# CY8C5868AXI_LP035 register map
File version: 0.1
CY8C58LP
Registers are 8-bit, read-write, no defined reset value unless marked. A register's access mark holds for its fields unless they carry their own. Offsets are from the block's base; lines under a group give offsets from that group; [hi:lo] are bit positions; {n}, {i} and the like mark numbered series; 'fields as' and 'values as' point back to an identical list; <NAME> marks a mode.

## Memory map
0x00000000 PWM_Regulering
0x00000000 PWM_Speed
0x00000000 Counter_Speed
0x00000000 AD_konverter_SAR — SAR ADC
0x00000000 UART

## PWM_Regulering
Base 0x00000000
0x40006428 PWM_Regulering_COMPARE_Reg_ — UDB.D0 - Assigned Compare Value
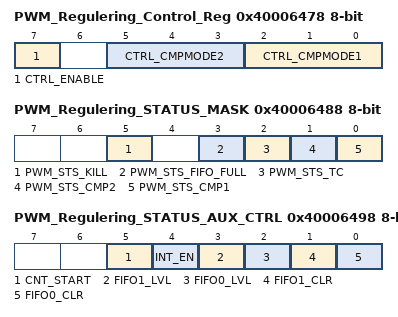
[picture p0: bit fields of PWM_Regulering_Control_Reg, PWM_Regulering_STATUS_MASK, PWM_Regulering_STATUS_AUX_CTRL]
0x40006478 PWM_Regulering_Control_Reg — UDB Control Register - Assigned Control Register Value
  [7] CTRL_ENABLE — Enable the PWM
  [5:3] CTRL_CMPMODE2 — Compare mode 2
  [2:0] CTRL_CMPMODE1 — Compare mode 1
0x40006488 PWM_Regulering_STATUS_MASK — UDB Status bits Interrupt Mask Enable Register
  [5] PWM_STS_KILL ro — Enables the Interrupt on Kill
  [3] PWM_STS_FIFO_FULL ro — FIFO Full Status Mask
  [2] PWM_STS_TC ro — Enables the Interrupt on Terminal Count
  [1] PWM_STS_CMP2 ro — Enables the Interrupt on Compare 2
  [0] PWM_STS_CMP1 ro — Enables the Interrupt on Compare 1
0x40006498 PWM_Regulering_STATUS_AUX_CTRL — UDB Auxilliary Control Register
  [5] CNT_START — FIFO0 clear
    0=E_CNT_START0 (Disable counter); 1=E_CNT_START1 (Enable counter)
  [4] INT_EN
    0=E_INT_EN0 (Interrupt disabled); 1=E_INT_EN1 (Interrupt enabled)
  [3] FIFO1_LVL — FIFO level
    0=E_FIFO_LVL_0 (FIFO LVL: input mode: FIFO not full; output mode: FIFO not empty); 1=E_FIFO_LVL_1 (FIFO LVL: input mode: FIFO at least 1/2 empty; output mode: FIFO at least 1/2 full)
  [2] FIFO0_LVL — FIFO level
    values as FIFO1_LVL
  [1] FIFO1_CLR — FIFO1 clear
    0=E_FIFO_CLR_0 (Normal FIFO operation); 1=E_FIFO_CLR_1 (Clear FIFO state)
  [0] FIFO0_CLR — FIFO0 clear
    values as FIFO1_CLR

## PWM_Speed
Base 0x00000000
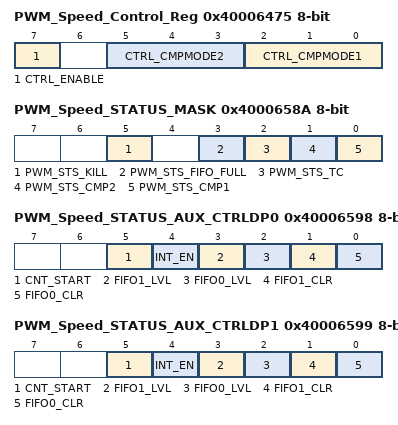
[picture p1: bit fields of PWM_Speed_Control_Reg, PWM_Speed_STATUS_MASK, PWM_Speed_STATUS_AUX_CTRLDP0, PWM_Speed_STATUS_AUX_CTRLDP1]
0x40006475 PWM_Speed_Control_Reg — UDB Control Register - Assigned Control Register Value
  [7] CTRL_ENABLE — Enable the PWM
  [5:3] CTRL_CMPMODE2 — Compare mode 2
  [2:0] CTRL_CMPMODE1 — Compare mode 1
0x40006528 PWM_Speed_COMPARE_Reg 16-bit — UDB.D0 - Assigned Compare Value
0x4000658A PWM_Speed_STATUS_MASK — UDB Status bits Interrupt Mask Enable Register
  fields as PWM_Regulering.PWM_Regulering_STATUS_MASK
0x40006598 PWM_Speed_STATUS_AUX_CTRLDP0 — UDB Auxilliary Control Register
  fields as PWM_Regulering.PWM_Regulering_STATUS_AUX_CTRL
0x40006599 PWM_Speed_STATUS_AUX_CTRLDP1 — UDB Auxilliary Control Register
  fields as PWM_Regulering.PWM_Regulering_STATUS_AUX_CTRL

## Counter_Speed
Base 0x00000000
0x40006409 Counter_Speed_COUNTER 32-bit — UDB.A0 - Current Counter Value
0x40006429 Counter_Speed_PERIOD 32-bit — UDB.D0 - Assigned Period
0x40006439 Counter_Speed_COMPARE 32-bit — UDB.D1 - Assigned Compare Value
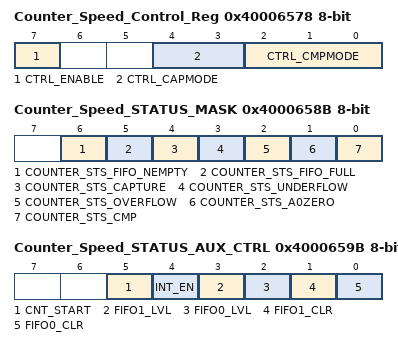
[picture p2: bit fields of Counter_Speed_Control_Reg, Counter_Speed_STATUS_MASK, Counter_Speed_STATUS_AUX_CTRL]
0x40006578 Counter_Speed_Control_Reg — UDB Control Register - Assigned Control Register Value
  [7] CTRL_ENABLE — Enable Counter
  [4:3] CTRL_CAPMODE — Capture mode
  [2:0] CTRL_CMPMODE — Compare mode
0x4000658B Counter_Speed_STATUS_MASK — UDB Status bits Interrupt Mask Enable Register
  [6] COUNTER_STS_FIFO_NEMPTY — FIFO Not Empty Status
  [5] COUNTER_STS_FIFO_FULL — FIFO Full Status
  [4] COUNTER_STS_CAPTURE — Capture Status
  [3] COUNTER_STS_UNDERFLOW — Underflow status
  [2] COUNTER_STS_OVERFLOW — Overflow status
  [1] COUNTER_STS_A0ZERO — A0 Zero ouput status
  [0] COUNTER_STS_CMP — Compare output status
0x4000659B Counter_Speed_STATUS_AUX_CTRL — UDB Auxilliary Control Register
  fields as PWM_Regulering.PWM_Regulering_STATUS_AUX_CTRL

## AD_konverter_SAR — SAR ADC
Base 0x00000000
0x40004616 SAR_TR0 — SAR trim register
{0x40005908+i} SAR_CSR{i} (i=0..6) — SAR status and control register {i}
0x40005B28 SAR_SW0 — SAR Analog Routing Register 0
{0x40005B28+i} SAR_SW{i} (i=2..4) — SAR Analog Routing Register {i}
0x40005B2E SAR_SW6 — SAR Analog Routing Register 6
0x40005B2F SAR_CLK — SAR Clock Selection Register
0x40005BA2 SAR_WRK 16-bit — SAR working register

## UART
Base 0x00000000
0x40006423 RX_UART_RX_ADDRESS1 — RX Address1 Register
0x40006433 RX_UART_RX_ADDRESS2 — RX Address2 Register
0x40006443 RX_UART_RX_DATA — RX Data Register
0x4000644E TX_UART_TX_DATA — TX Data Register
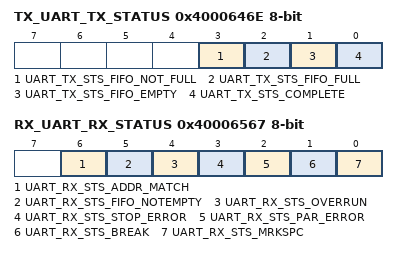
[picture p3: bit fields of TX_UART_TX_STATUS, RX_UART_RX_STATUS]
0x4000646E TX_UART_TX_STATUS — TX status register
  [3] UART_TX_STS_FIFO_NOT_FULL ro, [2] UART_TX_STS_FIFO_FULL ro, [1] UART_TX_STS_FIFO_EMPTY ro, [0] UART_TX_STS_COMPLETE ro
0x40006567 RX_UART_RX_STATUS — RX status register
  [6] UART_RX_STS_ADDR_MATCH ro, [5] UART_RX_STS_FIFO_NOTEMPTY ro, [4] UART_RX_STS_OVERRUN ro, [3] UART_RX_STS_STOP_ERROR ro, [2] UART_RX_STS_PAR_ERROR ro, [1] UART_RX_STS_BREAK ro, [0] UART_RX_STS_MRKSPC ro
